# A64 register map
Vendor: Allwinner; Series: A64; File version: 0.1
CPU: CA53 0, little endian, MPU, no FPU, 0 interrupt priority bits
Registers are 32-bit, read-write, reset 0x0 unless marked. A register's access mark holds for its fields unless they carry their own. Offsets are from the block's base; [hi:lo] are bit positions; lines under a group give offsets from that group; {n}, {i} and the like mark numbered series; 'fields as' and 'values as' point back to an identical list.

## TCON0
Base 0x01C0C000
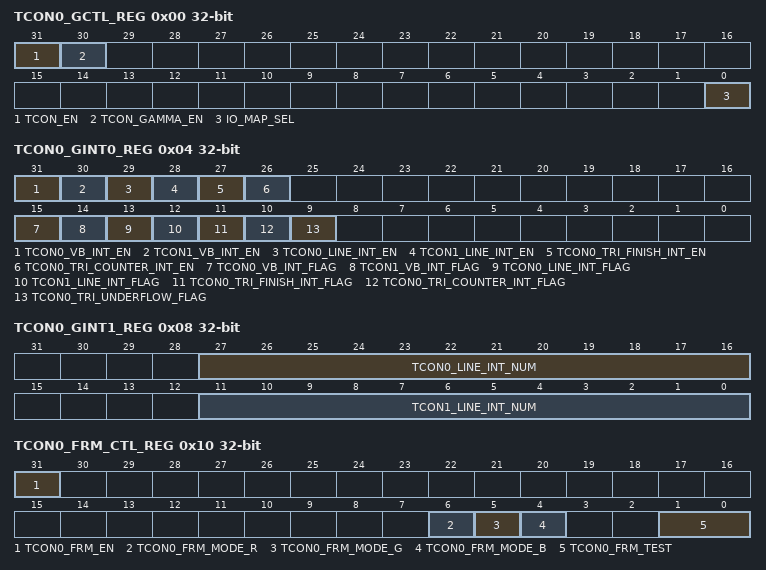
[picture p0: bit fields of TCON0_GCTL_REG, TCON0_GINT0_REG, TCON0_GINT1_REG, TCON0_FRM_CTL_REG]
0x00 TCON0_GCTL_REG
  [31] TCON_EN — 0: disable 1: enable When it`s disabled, the module will be reset to idle state.
    0=disable; 1=enable When it`s disabled, the module will be reset to idle state
  [30] TCON_GAMMA_EN — 0: disable 1: enable
    0=disable; 1=enable
  [0] IO_MAP_SEL — 0: TCON0 1: TCON1 Note: this bit determined which IO_INV/IO_TRI are valid
    0=TCON0; 1=TCON1 (TCON1 Note: this bit determined which IO_INV/IO_TRI are valid)
0x04 TCON0_GINT0_REG
  [31] TCON0_VB_INT_EN — 0: disable 1: enable
    0=disable; 1=enable
  [30] TCON1_VB_INT_EN — 0: disable 1: enable
    0=disable; 1=enable
  [29] TCON0_LINE_INT_EN — 0: disable 1: enable
    0=disable; 1=enable
  [28] TCON1_LINE_INT_EN — 0: disable 1: enable
    0=disable; 1=enable
  [27] TCON0_TRI_FINISH_INT_EN — 0: disable 1: enable
    0=disable; 1=enable
  [26] TCON0_TRI_COUNTER_INT_EN — 0: disable 1: enable
    0=disable; 1=enable
  [15] TCON0_VB_INT_FLAG — Asserted during vertical no-display period every frame. Write 0 to clear it.
  [14] TCON1_VB_INT_FLAG — Asserted during vertical no-display period every frame. Write 0 to clear it.
  [13] TCON0_LINE_INT_FLAG — Trigger when SY0 match the current TCON0 scan line Write 0 to clear it.
  [12] TCON1_LINE_INT_FLAG — Trigger when SY1 match the current TCON1 scan line Write 0 to clear it.
  [11] TCON0_TRI_FINISH_INT_FLAG — Trigger when cpu trigger mode finish Write 0 to clear it.
  [10] TCON0_TRI_COUNTER_INT_FLAG — Trigger when tri counter reache this value Write 0 to clear it.
  [9] TCON0_TRI_UNDERFLOW_FLAG — Only used in dsi video mode, tri when sync by dsi but not finish Write 0 to clear it.
0x08 TCON0_GINT1_REG
  [27:16] TCON0_LINE_INT_NUM — scan line for TCON0 line trigger(including inactive lines) Setting it for the specified line for trigger0. Note: SY0 is writable only when LINE_TRG0 disable.
  [11:0] TCON1_LINE_INT_NUM — scan line for TCON1 line trigger(including inactive lines) Setting it for the specified line for trigger 1. Note: SY1 is writable only when LINE_TRG1 disable.
0x10 TCON0_FRM_CTL_REG — TCON FRM control register
  [31] TCON0_FRM_EN — 0:disable 1:enable
  [6] TCON0_FRM_MODE_R — 0: 6bit frm output 1: 5bit frm output
    0=6bit frm output; 1=5bit frm output
  [5] TCON0_FRM_MODE_G — 0: 6bit frm output 1: 5bit frm output
    0=6bit frm output; 1=5bit frm output
  [4] TCON0_FRM_MODE_B — 0: 6bit frm output 1: 5bit frm output
    0=6bit frm output; 1=5bit frm output
  [1:0] TCON0_FRM_TEST — 00: FRM 01: half 5/6bit, half FRM 10: half 8bit, half FRM 11: half 8bit, half 5/6bit
{0x14+4i} TCON0_FRM_SEED_REG[{i}] (i=0..5) — TCON FRM seed register (N=0,1,2,3,4,5)
  [24:0] SEED_VALUE — N=0: Pixel_Seed_R N=1: Pixel_Seed_G N=2: Pixel_Seed_B N=3: Line_Seed_R N=4: Line_Seed_G N=5: Line_Seed_B Note: avoid set it to 0
{0x2C+4i} TCON0_FRM_TAB_REG[{i}] (i=0..3) — TCON FRM table register (N=0,1,2,3)
  [31:0] FRM_TABLE_VALUE
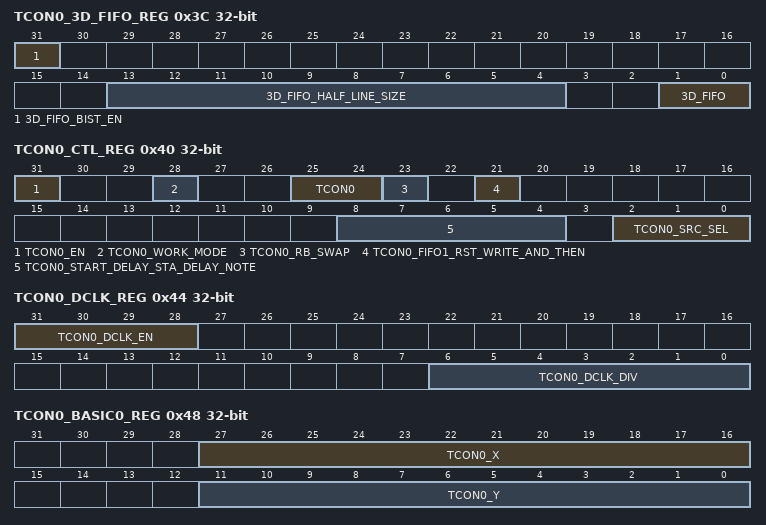
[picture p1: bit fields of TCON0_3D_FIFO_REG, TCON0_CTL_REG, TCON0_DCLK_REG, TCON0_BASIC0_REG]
0x3C TCON0_3D_FIFO_REG — TCON0 3D fifo register
  [31] 3D_FIFO_BIST_EN — 0: disable 1: enable
    0=disable; 1=enable
  [13:4] 3D_FIFO_HALF_LINE_SIZE — Note: The number of data in half line=3D_FIFO_HALF_LINE_SIZE+1 only valid when 3D_FIFO_SETTING set as 2
  [1:0] 3D_FIFO — 0: by pass 1: used as normal FIFO 2: used as 3D interlace FIFO 3: reserved
0x40 TCON0_CTL_REG — TCON0 control register
  [31] TCON0_EN — TCON0_En 0: disable 1: enable Note: It executes at the beginning of the first blank line of TCON0 timing.
    0=disable; 1=enable Note: It executes at the beginning of the first blank line of TCON0 timing
  [28] TCON0_WORK_MODE — TCON0_Work_Mode 0: normal 1: dynamic freq
    0=normal; 1=dynamic freq
  [25:24] TCON0 — TCON0_IF 00: HV(Sync+DE) 01: 8080 I/F 1x:reservd
    0=HV_openingparen_Sync_plus_DE_closingparen_ (HV(Sync+DE)); 1=8080 I/F 1x:reservd
  [23] TCON0_RB_SWAP — TCON0_RB_Swap 0: default 1: swap RED and BLUE data at FIFO1
    0=default; 1=swap RED and BLUE data at FIFO1
  [21] TCON0_FIFO1_RST_WRITE_AND_THEN — TCON0_FIFO1_Rst Write 1 and then 0 at this bit will reset FIFO 1 Note: 1 holding time must more than 1 DCLK
  [8:4] TCON0_START_DELAY_STA_DELAY_NOTE — TCON0_Start_Delay STA delay NOTE: valid only when TCON0_EN == 1
  [2:0] TCON0_SRC_SEL — TCON0_SRC_SEL: 000: DE0 001: reserved 010: reserved 011: reserved 100: Test Data all 0 101: Test Data all 1 11x: reserved
0x44 TCON0_DCLK_REG — TCON0 data clock register
  [31:28] TCON0_DCLK_EN — LCLK_EN[3:0] :TCON0 clock enable 4'h0, 'h4,4'h6,4'ha7:dclk_en=0;dclk1_en=0;dclk2_en=0;dclkm2_en=0; 4'h1: dclk_en = 1; dclk1_en = 0; dclk2_en = 0; dclkm2_en = 0; 4'h2: dclk_en = 1; dclk1_en = 0; dclk2_en = 0; dclkm2_en = 1; 4'h3: dclk_en = 1; dclk1_en = 1; dclk2_en = 0; dclkm2_en = 0; 4'h5: dclk_en = 1; dclk1_en = 0; dclk2_en = 1; dclkm2_en = 0; 4'h8,4'h9,4'ha,4'hb,4'hc,4'hd,4'he,4'hf: dclk_en = 1; dclk1_en = 1; dclk2_en = 1; dclkm2_en = 1;
  [6:0] TCON0_DCLK_DIV — Tdclk = Tsclk * DCLKDIV Note: 1.if dclk1&dclk2 used DCLKDIV >=6 2.if dclk only DCLKDIV >=1
0x48 TCON0_BASIC0_REG — TCON0 basic timing register0
  [27:16] TCON0_X — Panel width is X+1
  [11:0] TCON0_Y — Panel height is Y+1
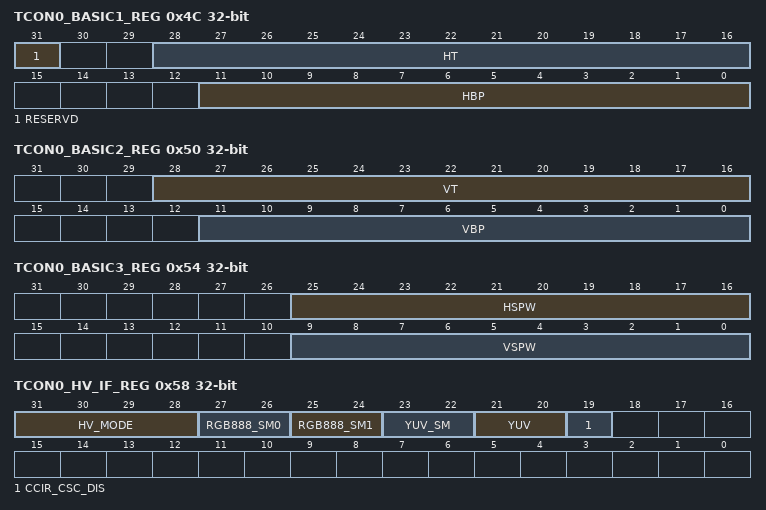
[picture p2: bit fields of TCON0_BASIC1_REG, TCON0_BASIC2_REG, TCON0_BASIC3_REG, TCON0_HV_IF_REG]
0x4C TCON0_BASIC1_REG — TCON0 basic timing register1
  [31] RESERVD
  [28:16] HT — Thcycle = (HT+1) * Tdclk Computation 1) parallel:HT = X + BLANK Limitation: 1) parallel :HT >= (HBP +1) + (X+1) +2 2) serial 1: HT >= (HBP +1) + (X+1) *3+2 3) serial 2: HT >= (HBP +1) + (X+1) *3/2+2
  [11:0] HBP — horizontal back porch (in dclk) Thbp = (HBP +1) * Tdclk
0x50 TCON0_BASIC2_REG — TCON0 basic timing register2
  [28:16] VT — TVT = (VT)/2 * Thsync Note: VT/2 >= (VBP+1 ) + (Y+1) +2
  [11:0] VBP — Tvbp = (VBP +1) * Thsync
0x54 TCON0_BASIC3_REG — TCON0 basic timing register3
  [25:16] HSPW — Thspw = (HSPW+1) * Tdclk Note: HT> (HSPW+1)
  [9:0] VSPW — Tvspw = (VSPW+1) * Thsync Note: VT/2 > (VSPW+1)
0x58 TCON0_HV_IF_REG — TCON0 hv panel interface register
  [31:28] HV_MODE — 0000: 24bit/1cycle parallel mode 1000: 8bit/3cycle RGB serial mode(RGB888) 1010: 8bit/4cycle Dummy RGB(DRGB) 1011: 8bit/4cycle RGB Dummy(RGBD) 1100: 8bit/2cycle YUV serial mode(CCIR656)
    0=_24bit_slash_1cycle_parallel_mode (24bit/1cycle parallel mode); 8=_8bit_slash_3cycle_RGB (8bit/3cycle RGB serial mode(RGB888)); 10=_8bit_slash_4cycle_Dummy (8bit/4cycle Dummy RGB(DRGB)); 11=_8bit_slash_4cycle_RGB (8bit/4cycle RGB Dummy(RGBD)); 12=_8bit_slash_2cycle_YUV (8bit/2cycle YUV serial mode(CCIR656))
  [27:26] RGB888_SM0 — serial RGB888 mode Output sequence at odd lines of the panel (line 1, 3, 5, 7...) 00: R G B 01: B R G 10: G B R 11: R G B
  [25:24] RGB888_SM1 — serial RGB888 mode Output sequence at even lines of the panel (line 2, 4, 6, 8...) 00: R G B 01: B R G 10: G B R 11: R G B
  [23:22] YUV_SM — serial YUV mode Output sequence 2-pixel-pair of every scan line 00: YUYV 01: YVYU 10: UYVY 11: VYUY
    0=YUYV; 1=YVYU; 2=UYVY; 3=VYUY
  [21:20] YUV — EAV/SAV F line delay 0:F toggle right after active video line 1:delay 2 line(CCIR PAL) 2:delay 3 line(CCIR NTSC) 3:reserved
  [19] CCIR_CSC_DIS — 0: enable 1: disable Only valid when HV mode is `1100`, select `0` TCON convert source from RGB to YUV
    0=enable; 1=disable Only valid when HV mode is `1100`, select `0` TCON convert source from RGB to YUV
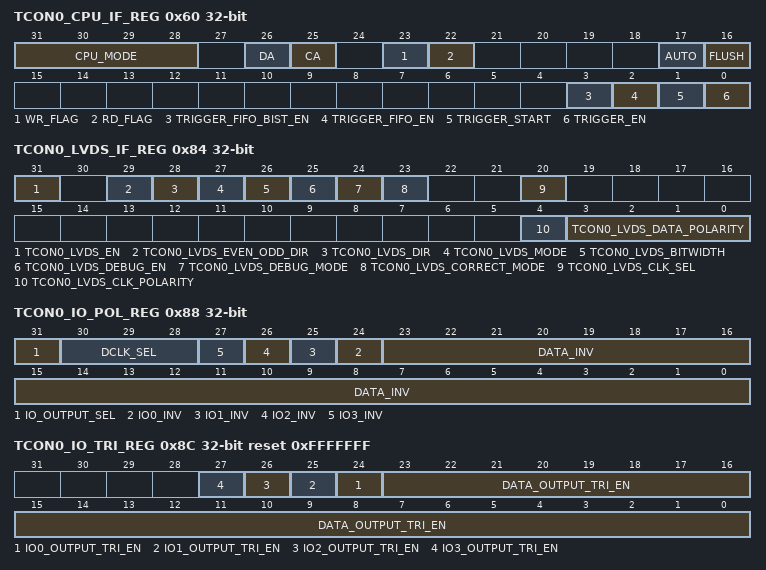
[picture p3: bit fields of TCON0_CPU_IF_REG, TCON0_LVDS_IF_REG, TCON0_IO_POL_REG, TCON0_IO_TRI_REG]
0x60 TCON0_CPU_IF_REG — TCON0 cpu panel interface register
  [31:28] CPU_MODE — 0000: 18bit/256K mode 0010: 16bit mode0 0100: 16bit mode1 0110: 16bit mode2 1000: 16bit mode3 1010: 9bit mode 1100: 8bit 256K mode 1110: 8bit 65K mode xxx1: 24bit for DSI
    0=_18bit_slash_256K_mode (18bit/256K mode); 2=_16bit_mode0; 4=_16bit_mode1; 6=_16bit_mode2; 8=_16bit_mode3; 10=_9bit_mode; 12=_8bit_256K_mode; 14=_8bit_65K_mode; 1=24bit for DSI
  [26] DA — pin A1 value in 8080 mode auto/flash states
  [25] CA — pin A1 value in 8080 mode WR/RD execute
  [23] WR_FLAG ro — 0:write operation is finishing 1:write operation is pending
  [22] RD_FLAG ro — 0:read operation is finishing 1:read operation is pending
  [17] AUTO — auto Transfer Mode: If it`s 1, all the valid data during this frame are write to panel. Note: This bit is sampled by Vsync
  [16] FLUSH — direct transfer mode: If it`s enabled, FIFO1 is regardless of the HV timing, pixels data keep being transferred unless the input FIFO was empty. Data output rate control by DCLK.
  [3] TRIGGER_FIFO_BIST_EN — 0: disable 1: enable Entry addr is 0xFF8
    0=disable; 1=enable Entry addr is 0xFF8
  [2] TRIGGER_FIFO_EN — 0:enable 1:disable
  [1] TRIGGER_START — write `1` to start a frame flush, write`0` has no effect. this flag indicated frame flush is running sofeware must make sure write `1` only when this flag is `0`.
  [0] TRIGGER_EN — 0: trigger mode disable 1: trigger mode enable
    0=disable (trigger mode disable); 1=enable (trigger mode enable)
0x64 TCON0_CPU_WR_REG — TCON0 cpu panel write data register
  [23:0] DATA_WR wo — data write on 8080 bus, launch a write operation on 8080 bus
0x68 TCON0_CPU_RD0_REG reset not defined — TCON0 cpu panel read data register0
  [23:0] DATA_RD0 ro — Data_Rd0 data read on 8080 bus, launch a new read operation on 8080 bus
0x6C TCON0_CPU_RD1_REG reset not defined — TCON0 cpu panel read data register1
  [23:0] DATA_RD1 ro — Data_Rd1 data read on 8080 bus, without a new read operation on 8080 bus
0x84 TCON0_LVDS_IF_REG — TCON0 lvds panel interface register
  [31] TCON0_LVDS_EN — 0: disable 1: enable
    0=disable; 1=enable
  [29] TCON0_LVDS_EVEN_ODD_DIR — 0: normal 1: reverse
    0=normal; 1=reverse
  [28] TCON0_LVDS_DIR — 1: normal 2: reverse NOTE: LVDS direction
    1=normal
  [27] TCON0_LVDS_MODE — 0: NS mode 1: JEIDA mode
    0=NS_mode; 1=JEIDA_mode
  [26] TCON0_LVDS_BITWIDTH — 0: 24bit 1: 18bit
    0=_24bit; 1=_18bit
  [25] TCON0_LVDS_DEBUG_EN — 0: disable 1: enable
    0=disable; 1=enable
  [24] TCON0_LVDS_DEBUG_MODE — 0: mode0 RANDOM DATA 1: mode1 output CLK period=7/2 LVDS CLK period
    0=mode0 RANDOM DATA; 1=mode1 output CLK period=7/2 LVDS CLK period
  [23] TCON0_LVDS_CORRECT_MODE — 0: mode0 1: mode1
    0=mode0; 1=mode1
  [20] TCON0_LVDS_CLK_SEL — 0: MIPI PLL 1: TCON0 CLK
    0=MIPI (MIPI PLL); 1=TCON0 (TCON0 CLK)
  [4] TCON0_LVDS_CLK_POLARITY — 0: reverse 1: normal
    0=reverse; 1=normal
  [3:0] TCON0_LVDS_DATA_POLARITY — 0: reverse 1: normal
0x88 TCON0_IO_POL_REG — TCON0 IO polarity register
  [31] IO_OUTPUT_SEL — 0: normal output 1: register output when set as `1`, d[23:0], io0, io1,io3 sync to dclk
    0=normal output; 1=register output when set as `1`, d[23:0], io0, io1,io3 sync to dclk
  [30:28] DCLK_SEL — 000: used DCLK0(normal phase offset) 001: used DCLK1(1/3 phase offset) 010: used DCLK2(2/3 phase offset) 101: DCLK0/2 phase 0 100: DCLK0/2 phase 90 reserved
    0=used_DCLK0_openingparen_normal_phase (used DCLK0(normal phase offset)); 1=used_DCLK1_openingparen_1_slash_3_phase (used DCLK1(1/3 phase offset)); 2=used_DCLK2_openingparen_2_slash_3_phase (used DCLK2(2/3 phase offset)); 5=DCLK0_slash_2_phase_0 (DCLK0/2 phase 0); 4=DCLK0_slash_2_phase_90 (DCLK0/2 phase 90 reserved)
  [n+24] IO{n}_INV (n=0..3) — 0: not invert 1: invert
    0=not_invert; 1=invert
  [23:0] DATA_INV — TCON0 output port D[23:0] polarity control, with independent bit control: 0s: normal polarity 1s: invert the specify output
0x8C TCON0_IO_TRI_REG reset 0xFFFFFFF — TCON0 IO trigger register
  [n+24] IO{n}_OUTPUT_TRI_EN (n=0..3) — 1: disable 0: enable
    1=disable; 0=enable
  [23:0] DATA_OUTPUT_TRI_EN — TCON0 output port D[23:0] output enable, with independent bit control: 1s: disable 0s: enable
0x100 TCON0_CEU_CTL_REG
  [31] CEU_EN — CEU_en 0: bypass 1: enable
    0=bypass; 1=enable
0x110 TCON0_CEU_COEF_MUL_REG_0
  [12:0] CEU_COEF_MUL_VALUE — signed 13bit value, range of (-16,16) N=0: Rr N=1: Rg N=2: Rb N=4: Gr N=5: Gg N=6: Gb N=8: Br N=9: Bg N=10: Bb
0x114 TCON0_CEU_COEF_MUL_REG_1 — TCON0_CEU_COEF_MUL_REG_0
  fields as TCON0_CEU_COEF_MUL_REG_0
0x118 TCON0_CEU_COEF_MUL_REG_2 — TCON0_CEU_COEF_MUL_REG_0
  fields as TCON0_CEU_COEF_MUL_REG_0
{0x11C+0x10*i} _N[{i}] (i=0..2) group
  0x00 TCON0_CEU_COEF_ADD_REG
    [18:0] CEU_COEF_ADD_VALUE — signed 19bit value, range of (-16384, 16384) N=0: Rc N=1: Gc N=2: Bc
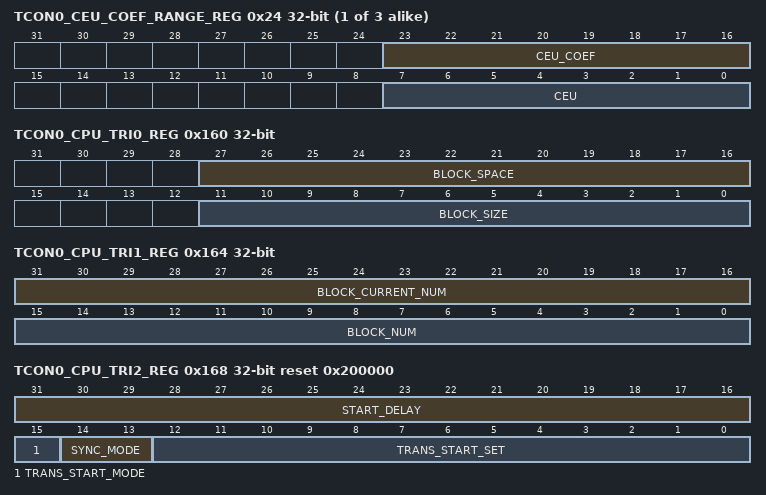
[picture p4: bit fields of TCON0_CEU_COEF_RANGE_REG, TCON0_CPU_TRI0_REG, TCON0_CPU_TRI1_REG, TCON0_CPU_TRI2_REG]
  0x24 TCON0_CEU_COEF_RANGE_REG
    [23:16] CEU_COEF — _Range_Min unsigned 8bit value, range of [0,255]
    [7:0] CEU — Coef _Range_Max unsigned 8bit value, range of [0,255]
{0x110+4i} TCON0_CEU_COEF_MUL_REG_{i} (i=4..6) — TCON0_CEU_COEF_MUL_REG_0
  fields as TCON0_CEU_COEF_MUL_REG_0
{0x110+4i} TCON0_CEU_COEF_MUL_REG_{i} (i=8..10) — TCON0_CEU_COEF_MUL_REG_0
  fields as TCON0_CEU_COEF_MUL_REG_0
0x160 TCON0_CPU_TRI0_REG — TCON0 cpu panel trigger register0
  [27:16] BLOCK_SPACE — should be set >20*pixel_cycle
  [11:0] BLOCK_SIZE
0x164 TCON0_CPU_TRI1_REG — TCON0 cpu panel trigger register1
  [31:16] BLOCK_CURRENT_NUM ro, [15:0] BLOCK_NUM
0x168 TCON0_CPU_TRI2_REG reset 0x200000 — TCON0 cpu panel trigger register2
  [31:16] START_DELAY — Tdly = (Start_Delay +1) * be_clk*8
  [15] TRANS_START_MODE — 0: ecc_fifo+tri_fifo 1: tri_fifo
    0=ecc_fifo_plus_tri_fifo (ecc_fifo+tri_fifo); 1=tri_fifo
  [14:13] SYNC_MODE — 0x: auto 10: 0 11: 1
    2=_0; 3=_1
  [12:0] TRANS_START_SET
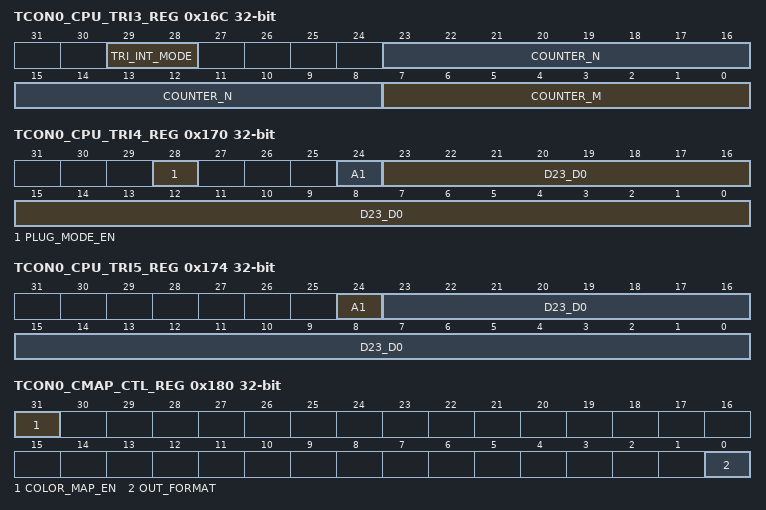
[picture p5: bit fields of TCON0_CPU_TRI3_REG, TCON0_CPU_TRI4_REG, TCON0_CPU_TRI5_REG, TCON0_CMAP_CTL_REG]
0x16C TCON0_CPU_TRI3_REG — TCON0 cpu panel trigger register3
  [29:28] TRI_INT_MODE — 00: disable 01: counter mode 10: te rising mode 11: te falling mode when set as 01, Tri_Counter_Int occur in cycle of (Count_N+1) (Count_M+1) 4 dclk. when set as 10 or 11, io0 is map as TE input.
  [23:8] COUNTER_N
  [7:0] COUNTER_M
0x170 TCON0_CPU_TRI4_REG — TCON0 cpu panel trigger register4
  [28] PLUG_MODE_EN — 0: disable 1:enable
    0=disable 1:enable
  [24] A1 — Valid in first Block
  [23:0] D23_D0 — Valid in first Block
0x174 TCON0_CPU_TRI5_REG — TCON0 cpu panel trigger register5
  [24] A1 — Valid in Block except first
  [23:0] D23_D0 — Valid in Block except first
0x180 TCON0_CMAP_CTL_REG
  [31] COLOR_MAP_EN — 0: bypass 1: enable This module only work when X is divided by 4
    0=bypass; 1=enable This module only work when X is divided by 4
  [0] OUT_FORMAT — 0: 4 pixel output mode: Out0 -> Out1 -> Out2 -> Out3 1: 2 pixel output mode: Out0 -> Out1
    0=4 pixel output mode: Out0 -> Out1 -> Out2 -> Out3; 1=2 pixel output mode: Out0 -> Out1
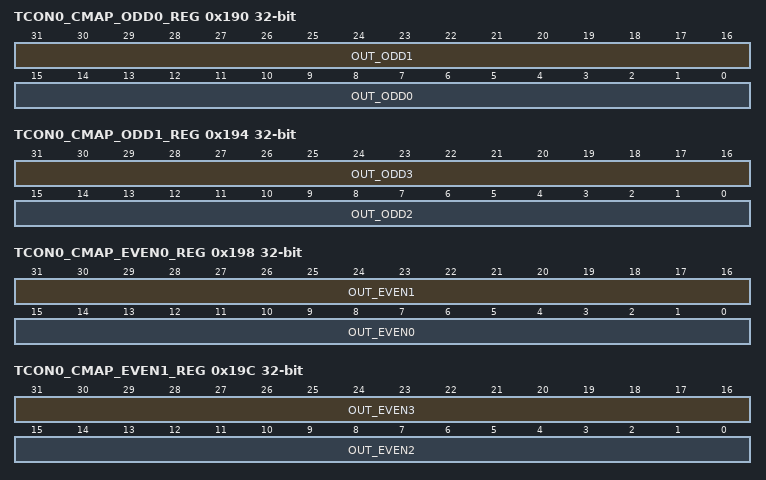
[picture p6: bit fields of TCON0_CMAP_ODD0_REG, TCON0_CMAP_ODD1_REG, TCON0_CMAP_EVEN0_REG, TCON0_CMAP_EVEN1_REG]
0x190 TCON0_CMAP_ODD0_REG
  [31:16] OUT_ODD1
  [15:0] OUT_ODD0 — Out_Odd0 bit15-12: Reservd bit11-08: Out_Odd0[23:16] bit07-04: Out_Odd0[15:8] bit03-00: Out_Odd0[7:0] 0x0: in_b0 0x1: in_g0 0x2: in_r0 0x3: reservd 0x4: in_b1 0x5: in_g1 0x6: in_r1 0x7: reservd 0x8: in_b2 0x9: in_g2 0xa: in_r2 0xb: reservd 0xc: in_b3 0xd: in_g3 0xe: in_r3 0xf: reservd
0x194 TCON0_CMAP_ODD1_REG
  [31:16] OUT_ODD3, [15:0] OUT_ODD2
0x198 TCON0_CMAP_EVEN0_REG
  [31:16] OUT_EVEN1, [15:0] OUT_EVEN0
0x19C TCON0_CMAP_EVEN1_REG
  [31:16] OUT_EVEN3, [15:0] OUT_EVEN2
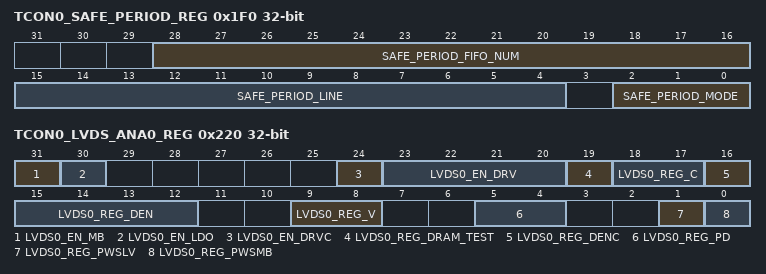
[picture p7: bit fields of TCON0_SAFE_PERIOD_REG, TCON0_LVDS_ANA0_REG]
0x1F0 TCON0_SAFE_PERIOD_REG
  [28:16] SAFE_PERIOD_FIFO_NUM
  [15:4] SAFE_PERIOD_LINE
  [2:0] SAFE_PERIOD_MODE — 0: unsafe 1: safe 2: safe at ecc_fifo_curr_num > safe_period_fifo_num 3: safe at 2 and safe at sync active 4: safe at line
0x220 TCON0_LVDS_ANA0_REG — TCON LVDS analog register0
  [31] LVDS0_EN_MB — lvds0_en_mb enable the bias circuit of the LVDS_Ana module
  [30] LVDS0_EN_LDO
  [24] LVDS0_EN_DRVC — lvds0_en_drvc enable all circuits working when transmitting the data in channel clock of LVDS_tx0
  [23:20] LVDS0_EN_DRV — lvds0_en_drv enable all circuits working when transmitting the data in channel<3:0> of LVDS_tx0
  [19] LVDS0_REG_DRAM_TEST — Lvds0_reg_dram_test 0:dram test clk disable 1:dram test clk enable
  [18:17] LVDS0_REG_C — lvds0_reg_c adjust current flowing through Rload of Rx to change the differential signals amplitude 0:250mV 1:300mV 2:350mV 3:400mV
  [16] LVDS0_REG_DENC — lvds0_reg_denc choose data output or PLL test clock output in LVDS_tx
  [15:12] LVDS0_REG_DEN — lvds0_reg_den choose data output or PLL test clock output in LVDS_tx
  [9:8] LVDS0_REG_V — lvds0_reg_v adjust common mode voltage of the differential signals in five channels single signal high level: 0:1.1V 1:1.19V 2:1.3V 3:1.43V
  [5:4] LVDS0_REG_PD — lvds0_reg_pd fine adjust the slew rate of output data
  [1] LVDS0_REG_PWSLV — lvds0_reg_pwslv adjust voltage amplitude of low power in LVDS_Ana
  [0] LVDS0_REG_PWSMB — lvds0_reg_pwsmb adjust voltage amplitude of mbias voltage reference in LVDS_Ana
